AUTOSAR XML (schema 4-2-2)
package /ComponentTypes
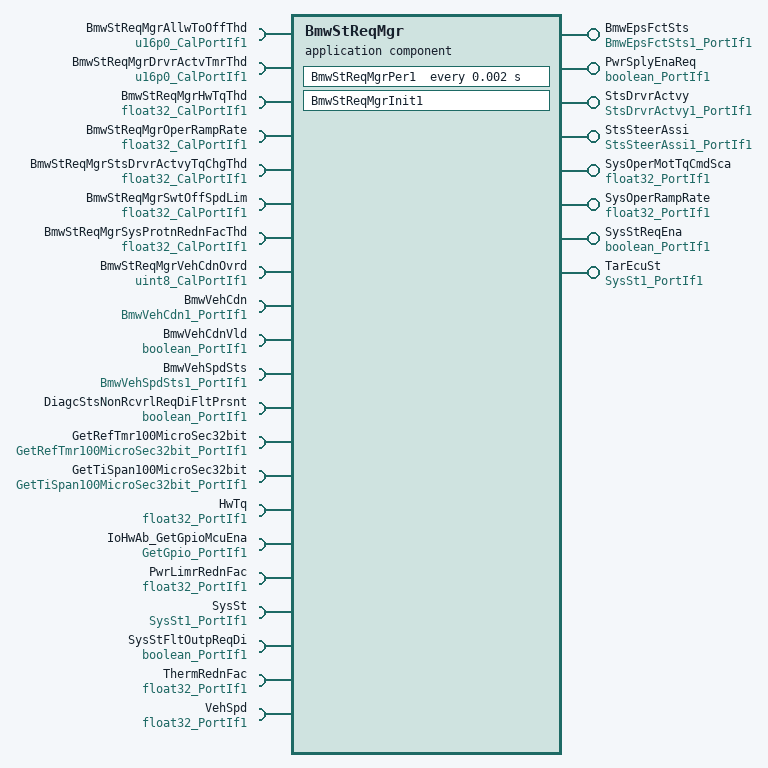
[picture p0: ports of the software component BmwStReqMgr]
  application sw component type BmwStReqMgr  # This function will be responsible for requesting transitions between the states and modes of the steering system based on vehicle signals
    8 x provide port:
      BmwEpsFctSts: nonqueued-sender-com-spec{data-element=Val, init-value=128}, provided-interface=BmwEpsFctSts1_PortIf1  # Eps Function Status enumerated signal
      PwrSplyEnaReq: nonqueued-sender-com-spec{data-element=Logl, init-value=0}, provided-interface=boolean_PortIf1  # Power Supply Enable Request Signal
      StsDrvrActvy: nonqueued-sender-com-spec{data-element=Val, init-value=1}, provided-interface=StsDrvrActvy1_PortIf1  # Signal for Status Driver Activity
      StsSteerAssi: nonqueued-sender-com-spec{data-element=Val, init-value=0}, provided-interface=StsSteerAssi1_PortIf1  # Status Steering Assist
      SysOperMotTqCmdSca: nonqueued-sender-com-spec{data-element=Val, init-value=1}, provided-interface=float32_PortIf1  # System Operate Motor Torque Command Scale Signal
      SysOperRampRate: nonqueued-sender-com-spec{data-element=Val, init-value=1}, provided-interface=float32_PortIf1  # System Operate Ramp Rate Signal
      SysStReqEna: nonqueued-sender-com-spec{data-element=Logl, init-value=0}, provided-interface=boolean_PortIf1  # System State Request Enable Signal
      TarEcuSt: nonqueued-sender-com-spec{data-element=Val, init-value=3}, provided-interface=SysSt1_PortIf1  # Target ECU State Signal
    21 x require port:
      BmwStReqMgrAllwToOffThd: parameter-require-com-spec{init-value=500, parameter=Val}, required-interface=u16p0_CalPortIf1  # Time threshold for which state machine waits before going to OFF from DISABLE
      BmwStReqMgrDrvrActvTmrThd: parameter-require-com-spec{init-value=500, parameter=Val}, required-interface=u16p0_CalPortIf1  # Time threshold for which the Handwheel Torque must be below a threshold before setting Status Driver Activity to “No Driver Activity
      BmwStReqMgrHwTqThd: parameter-require-com-spec{init-value=0.4, parameter=Val}, required-interface=float32_CalPortIf1  # Handwheel Torque threshold for which the Status Driver Activity can be set to “No Driver Activity”, when Handwheel Torque is below this threshold for an amount of time
      BmwStReqMgrOperRampRate: parameter-require-com-spec{init-value=1, parameter=Val}, required-interface=float32_CalPortIf1  # Rate at which assist is applied and removed when applicable
      BmwStReqMgrStsDrvrActvyTqChgThd: parameter-require-com-spec{init-value=0.2, parameter=Val}, required-interface=float32_CalPortIf1  # Set Driver Status to Active when changes of HwTq are greater that this threshold
      BmwStReqMgrSwtOffSpdLim: parameter-require-com-spec{init-value=10, parameter=Val}, required-interface=float32_CalPortIf1  # Vehicle Speed threshold in which the valid Vehicle Speed signal is checked in certain conditions for Target ECU State transitions “Operate” to “Disable
      BmwStReqMgrSysProtnRednFacThd: parameter-require-com-spec{init-value=0.3, parameter=Val}, required-interface=float32_CalPortIf1  # Threshold for System Protection Reduction Factor used in the determination of Eps Function Status
      BmwStReqMgrVehCdnOvrd: parameter-require-com-spec{init-value=15, parameter=Val}, required-interface=uint8_CalPortIf1  # Override the BmwVehCdn to this value and BmwVehCdnVld to "true" if it is lower than BMWVEHCDN_INV(15).
      BmwVehCdn: nonqueued-receiver-com-spec{data-element=Val, filter=data-filter-type=ALWAYS, init-value=15}, required-interface=BmwVehCdn1_PortIf1  # Signal for BMW Vehicle Condition
      BmwVehCdnVld: nonqueued-receiver-com-spec{data-element=Logl, filter=data-filter-type=ALWAYS, init-value=0}, required-interface=boolean_PortIf1  # Signal for BMW Vehicle Condition Validity
      BmwVehSpdSts: nonqueued-receiver-com-spec{data-element=Val, filter=data-filter-type=ALWAYS, init-value=15}, required-interface=BmwVehSpdSts1_PortIf1  # Signal for BMW Vehicle Speed Status
      DiagcStsNonRcvrlReqDiFltPrsnt: nonqueued-receiver-com-spec{data-element=Logl, filter=data-filter-type=ALWAYS, init-value=0}, required-interface=boolean_PortIf1  # Signal to determine whether a Non-Recoverable Fault is present
      GetRefTmr100MicroSec32bit: client-com-spec=Oper, required-interface=GetRefTmr100MicroSec32bit_PortIf1  # Autosar Client to get the Reference time to calculate the elapsed time
      GetTiSpan100MicroSec32bit: client-com-spec=Oper, required-interface=GetTiSpan100MicroSec32bit_PortIf1  # Time Span
      HwTq: nonqueued-receiver-com-spec{data-element=Val, filter=data-filter-type=ALWAYS, init-value=0}, required-interface=float32_PortIf1  # Signal for Handwheel Torque
      IoHwAb_GetGpioMcuEna: client-com-spec=Oper, required-interface=GetGpio_PortIf1  # Output to be used in logic
      PwrLimrRednFac: nonqueued-receiver-com-spec{data-element=Val, filter=data-filter-type=ALWAYS, init-value=0}, required-interface=float32_PortIf1  # Power Limiter Reduction Factor
      SysSt: nonqueued-receiver-com-spec{data-element=Val, filter=data-filter-type=ALWAYS, init-value=3}, required-interface=SysSt1_PortIf1  # Signal for System State
      SysStFltOutpReqDi: nonqueued-receiver-com-spec{data-element=Logl, filter=data-filter-type=ALWAYS, init-value=0}, required-interface=boolean_PortIf1  # Signal to determine a fault is present that will request a transition to disable
      ThermRednFac: nonqueued-receiver-com-spec{data-element=Val, filter=data-filter-type=ALWAYS, init-value=0}, required-interface=float32_PortIf1  # Signal Description for THermRednFac: Value representing the percent reduction in assist being produced by the ThermMotTqLim value
      VehSpd: nonqueued-receiver-com-spec{data-element=Val, filter=data-filter-type=ALWAYS, init-value=0}, required-interface=float32_PortIf1  # Signal for Vehicle Speed
    behavior BmwStReqMgr_InternalBehavior
      ar-typed-per-instance-memorys:
        4 x data, all with sw-calibration-access=READ-ONLY:
          BmwVehCdnLvngDurn: type=uint32  # Elapsed time timer
          DrvrActvRefTmr: type=uint32  # Elapsed time timer
          PrevHwTq: type=float32  # Variable to store the Previous value of Handwheel Torque
          PrevTarEcuSt: type=uint8  # Variable to store the State Machine in
      init event BmwStReqMgr_InitEvent: start-on-event=BmwStReqMgrInit1
      timing event TMT_BmwStReqMgrPer1: start-on-event=BmwStReqMgrPer1, period=0.002
      port-api-options:
        enable-take-address=false, error-handling=NO-TRANSFORMER-ERROR-HANDLING, indirect-api=false, port=BmwEpsFctSts
        enable-take-address=false, error-handling=NO-TRANSFORMER-ERROR-HANDLING, indirect-api=false, port=BmwStReqMgrAllwToOffThd
        enable-take-address=false, error-handling=NO-TRANSFORMER-ERROR-HANDLING, indirect-api=false, port=BmwStReqMgrDrvrActvTmrThd
        enable-take-address=false, error-handling=NO-TRANSFORMER-ERROR-HANDLING, indirect-api=false, port=BmwStReqMgrHwTqThd
        enable-take-address=false, error-handling=NO-TRANSFORMER-ERROR-HANDLING, indirect-api=false, port=BmwStReqMgrOperRampRate
        enable-take-address=false, error-handling=NO-TRANSFORMER-ERROR-HANDLING, indirect-api=false, port=BmwStReqMgrStsDrvrActvyTqChgThd
        enable-take-address=false, error-handling=NO-TRANSFORMER-ERROR-HANDLING, indirect-api=false, port=BmwStReqMgrSwtOffSpdLim
        enable-take-address=false, error-handling=NO-TRANSFORMER-ERROR-HANDLING, indirect-api=false, port=BmwStReqMgrSysProtnRednFacThd
        enable-take-address=false, error-handling=NO-TRANSFORMER-ERROR-HANDLING, indirect-api=false, port=BmwStReqMgrVehCdnOvrd
        enable-take-address=false, error-handling=NO-TRANSFORMER-ERROR-HANDLING, indirect-api=false, port=BmwVehCdn
        enable-take-address=false, error-handling=NO-TRANSFORMER-ERROR-HANDLING, indirect-api=false, port=BmwVehCdnVld
        enable-take-address=false, error-handling=NO-TRANSFORMER-ERROR-HANDLING, indirect-api=false, port=BmwVehSpdSts
        enable-take-address=false, error-handling=NO-TRANSFORMER-ERROR-HANDLING, indirect-api=false, port=DiagcStsNonRcvrlReqDiFltPrsnt
        enable-take-address=false, error-handling=NO-TRANSFORMER-ERROR-HANDLING, indirect-api=false, port=GetRefTmr100MicroSec32bit
        enable-take-address=false, error-handling=NO-TRANSFORMER-ERROR-HANDLING, indirect-api=false, port=GetTiSpan100MicroSec32bit
        enable-take-address=false, error-handling=NO-TRANSFORMER-ERROR-HANDLING, indirect-api=false, port=HwTq
        enable-take-address=false, error-handling=NO-TRANSFORMER-ERROR-HANDLING, indirect-api=false, port=IoHwAb_GetGpioMcuEna
        enable-take-address=false, error-handling=NO-TRANSFORMER-ERROR-HANDLING, indirect-api=false, port=PwrSplyEnaReq
        enable-take-address=false, error-handling=NO-TRANSFORMER-ERROR-HANDLING, indirect-api=false, port=StsDrvrActvy
        enable-take-address=false, error-handling=NO-TRANSFORMER-ERROR-HANDLING, indirect-api=false, port=StsSteerAssi
        enable-take-address=false, error-handling=NO-TRANSFORMER-ERROR-HANDLING, indirect-api=false, port=SysOperMotTqCmdSca
        enable-take-address=false, error-handling=NO-TRANSFORMER-ERROR-HANDLING, indirect-api=false, port=SysOperRampRate
        enable-take-address=false, error-handling=NO-TRANSFORMER-ERROR-HANDLING, indirect-api=false, port=SysSt
        enable-take-address=false, error-handling=NO-TRANSFORMER-ERROR-HANDLING, indirect-api=false, port=SysStFltOutpReqDi
        enable-take-address=false, error-handling=NO-TRANSFORMER-ERROR-HANDLING, indirect-api=false, port=SysStReqEna
        enable-take-address=false, error-handling=NO-TRANSFORMER-ERROR-HANDLING, indirect-api=false, port=TarEcuSt
        enable-take-address=false, error-handling=NO-TRANSFORMER-ERROR-HANDLING, indirect-api=false, port=VehSpd
      runnable BmwStReqMgrInit1  # Function initialization. Empty
        sync call SC_GetRefTmr100MicroSec32bit_Oper: operation=GetRefTmr100MicroSec32bit.Oper, timeout=0
      runnable BmwStReqMgrPer1  # Periodic functionality. It contains the State Machine that Feeds may other components. E.g. determines the Target ECU Sts.
        data-receive-point-by-arguments:
          10 x access:
            REC_BmwVehCdn_Val_1: accessed-variable=BmwVehCdn.Val
            REC_BmwVehCdnVld_Logl: accessed-variable=BmwVehCdnVld.Logl
            REC_DiagcStsNonRcvrlReqDiFltPrsnt_Logl: accessed-variable=DiagcStsNonRcvrlReqDiFltPrsnt.Logl
            REC_HwTq_Val: accessed-variable=HwTq.Val
            REC_PwrLimrRednFac_Val: accessed-variable=PwrLimrRednFac.Val
            REC_SysSt_Val: accessed-variable=SysSt.Val
            REC_SysStFltOutpReqDi_Logl: accessed-variable=SysStFltOutpReqDi.Logl
            REC_ThermRednFac_Val: accessed-variable=ThermRednFac.Val
            REC_VehSpd_Val: accessed-variable=VehSpd.Val
            REC_VehSpdSts_Val: accessed-variable=BmwVehSpdSts.Val
        data-send-points:
          8 x access:
            SEND_BmwEpsFctSts_Val: accessed-variable=BmwEpsFctSts.Val
            SEND_PwrSplyEnaReq_Logl: accessed-variable=PwrSplyEnaReq.Logl
            SEND_StsDrvrActvy_Val_1: accessed-variable=StsDrvrActvy.Val
            SEND_StsSteerAssi_Val: accessed-variable=StsSteerAssi.Val
            SEND_SysOperMotTqCmdSca_Val: accessed-variable=SysOperMotTqCmdSca.Val
            SEND_SysOperRampRate_Val: accessed-variable=SysOperRampRate.Val
            SEND_SysStReqEna_Logl: accessed-variable=SysStReqEna.Logl
            SEND_TarEcuSt_Val: accessed-variable=TarEcuSt.Val
        sync call SC_GetRefTmr100MicroSec32bit_Oper: operation=GetRefTmr100MicroSec32bit.Oper, timeout=0
        sync call SC_GetTiSpan100MicroSec32bit_Oper: operation=GetTiSpan100MicroSec32bit.Oper, timeout=0
        sync call SC_IoHwAb_GetGpioMcuEna_Oper: operation=IoHwAb_GetGpioMcuEna.Oper, timeout=0
  swc implementation BmwStReqMgr_Implementation: behavior=BmwStReqMgr_InternalBehavior
    code-descriptors:
      code Default: artifact-descriptors=autosar-engineering-object={short-label=Default, category=SWSRC}
